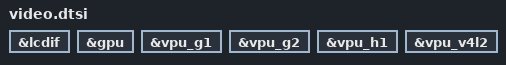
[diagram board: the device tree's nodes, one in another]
/**
 * Portenta-X8 dtb include file
 * Arduino 2023
 * Enables several video-related blocks such as gpu and vpus.
 */

&lcdif {
	status = "okay";
};

&gpu {
	status = "okay";
};

&vpu_g1 {
	status = "okay";
};

&vpu_g2 {
	status = "okay";
};

&vpu_h1 {
	status = "okay";
};

&vpu_v4l2 {
	status = "okay";
};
